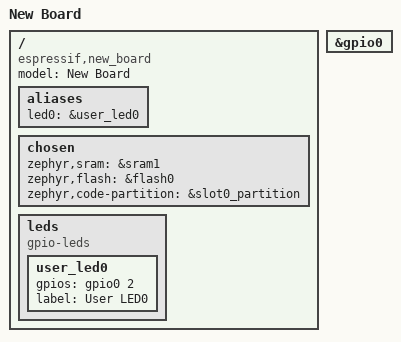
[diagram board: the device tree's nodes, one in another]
/dts-v1/;

#include <espressif/esp32/esp32_wrover_e_n4r8.dtsi>
#include <zephyr/dt-bindings/input/input-event-codes.h>
#include <zephyr/dt-bindings/input/esp32-touch-sensor-input.h>
#include <espressif/partitions_0x1000_amp.dtsi>

/  {
    model = "New Board";
	compatible = "espressif,new_board";
    
    aliases {
		led0 = &user_led0;
	};

    chosen {
		zephyr,sram = &sram1;
		zephyr,flash = &flash0;
		zephyr,code-partition = &slot0_partition;
	};

    leds {
        compatible = "gpio-leds";

        user_led0: user_led0 {
            gpios = <&gpio0 2 GPIO_ACTIVE_HIGH>;
            label = "User LED0";
        };
    };
};

&gpio0 {
	status = "okay";
};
